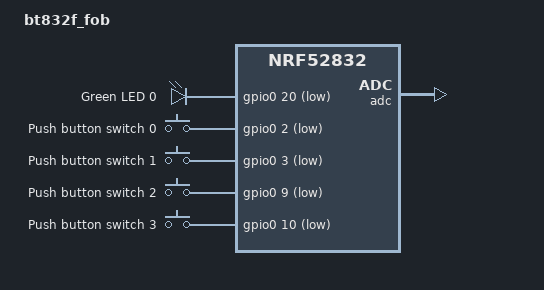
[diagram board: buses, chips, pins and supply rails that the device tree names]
// Copyright (c) 2024 Nordic Semiconductor ASA
// SPDX-License-Identifier: Apache-2.0

/dts-v1/;
#include <nordic/nrf52832_qfaa.dtsi>
#include <zephyr/dt-bindings/input/input-event-codes.h>

/ {
	model = "bt832f_fob";
	compatible = "touchtronics,bt832f-fob";

	chosen {
		zephyr,sram = &sram0;
		zephyr,flash = &flash0;
		zephyr,code-partition = &slot0_partition;
	};


	leds {
		compatible = "gpio-leds";
		led0: led_0 {
			gpios = <&gpio0 20 GPIO_ACTIVE_LOW>;
			label = "Green LED 0";
		};
	};

	buttons {
		compatible = "gpio-keys";
		button0: button_0 {
			label = "Push button switch 0";
			gpios = <&gpio0 2 (GPIO_PULL_UP | GPIO_ACTIVE_LOW)>;
			zephyr,code = <INPUT_KEY_0>;
		};
		button1: button_1 {
			label = "Push button switch 1";
			gpios = <&gpio0 3 (GPIO_PULL_UP | GPIO_ACTIVE_LOW)>;
			zephyr,code = <INPUT_KEY_1>;
		};
		button2: button_2 {
			label = "Push button switch 2";
			gpios = <&gpio0 9 (GPIO_PULL_UP | GPIO_ACTIVE_LOW)>;
			zephyr,code = <INPUT_KEY_2>;
		};
		button3: button_3 {
			label = "Push button switch 3";
			gpios = <&gpio0 10 (GPIO_PULL_UP | GPIO_ACTIVE_LOW)>;
			zephyr,code = <INPUT_KEY_3>;
		};
	};

	/* These aliases are provided for compatibility with samples */
	aliases {
		led0 = &led0;
		sw0 = &button0;
		sw1 = &button1;
		sw2 = &button2;
		sw3 = &button3;
	};
};

&adc {
	status = "okay";
};

&uicr {
	gpio-as-nreset;
};

&gpiote {
	status = "okay";
};

&gpio0 {
	status = "okay";
};

&flash0 {
	partitions {
		compatible = "fixed-partitions";
		#address-cells = <1>;
		#size-cells = <1>;

		boot_partition: partition@0 {
			label = "mcuboot";
			reg = <0x0 0xc000>;
		};
		slot0_partition: partition@c000 {
			label = "image-0";
			reg = <0xc000 0x32000>;
		};
		slot1_partition: partition@3e000 {
			label = "image-1";
			reg = <0x3e000 0x32000>;
		};
		scratch_partition: partition@70000 {
			label = "image-scratch";
			reg = <0x70000 0xa000>;
		};
		storage_partition: partition@7a000 {
			label = "storage";
			reg = <0x7a000 0x6000>;
		};
	};
};




